# APM32F423 register map
File version: 1.0
CPU: CM4 r1p0, little endian, no MPU, no FPU, 4 interrupt priority bits
Registers are 32-bit, read-write, reset 0x0 unless marked. A register's access mark holds for its fields unless they carry their own. Offsets are from the block's base; [hi:lo] are bit positions; {n}, {i} and the like mark numbered series.

## OTG_FS1_GLOBAL — USB on the go full speed
Base 0x50000000
Same registers: OTG_FS2_GLOBAL 0x40040000
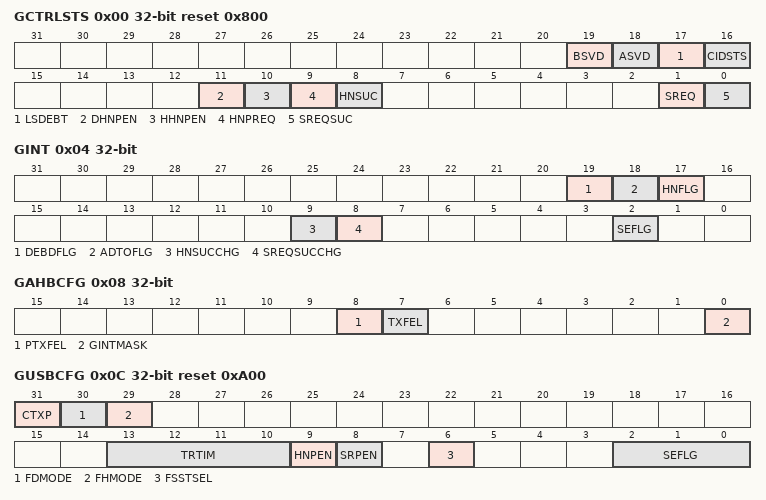
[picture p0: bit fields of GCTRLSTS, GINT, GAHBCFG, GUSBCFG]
0x00 GCTRLSTS access per field reset 0x800 — OTG_FS control and status register (OTG_FS_GOTGCTL)
  [19] BSVD ro — B-session valid
  [18] ASVD ro — A-session valid
  [17] LSDEBT ro — Long/short debounce time
  [16] CIDSTS ro — Connector ID status
  [11] DHNPEN rw — Device HNP enabled
  [10] HHNPEN rw — Host set HNP enable
  [9] HNPREQ rw — HNP request
  [8] HNSUC ro — Host negotiation success
  [1] SREQ rw — Session request
  [0] SREQSUC ro — Session request success
0x04 GINT — OTG_FS interrupt register (OTG_FS_GOTGINT)
  [19] DEBDFLG — Debounce done
  [18] ADTOFLG — A-device timeout change
  [17] HNFLG — Host negotiation detected
  [9] HNSUCCHG — Host negotiation success status change
  [8] SREQSUCCHG — Session request success status change
  [2] SEFLG — Session end detected
0x08 GAHBCFG — OTG_FS AHB configuration register (OTG_FS_GAHBCFG)
  [8] PTXFEL — Periodic TxFIFO empty level
  [7] TXFEL — TxFIFO empty level
  [0] GINTMASK — Global interrupt mask
0x0C GUSBCFG access per field reset 0xA00 — OTG_FS USB configuration register (OTG_FS_GUSBCFG)
  [31] CTXP rw — Corrupt Tx packet
  [30] FDMODE rw — Force device mode
  [29] FHMODE rw — Force host mode
  [13:10] TRTIM rw — USB turnaround time
  [9] HNPEN rw — HNP-capable
  [8] SRPEN rw — SRP-capable
  [6] FSSTSEL wo — Full Speed serial transceiver select
  [2:0] SEFLG rw — FS timeout calibration
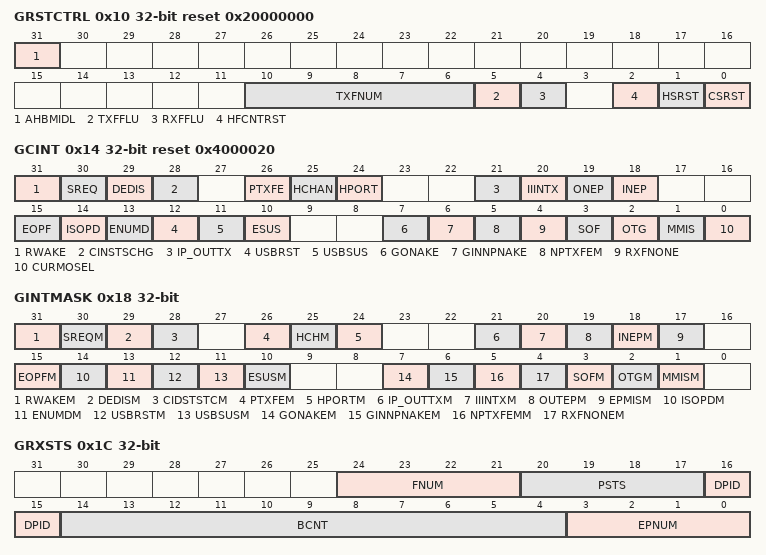
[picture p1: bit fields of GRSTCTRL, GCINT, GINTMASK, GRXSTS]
0x10 GRSTCTRL access per field reset 0x20000000 — OTG_FS reset register (OTG_FS_GRSTCTL)
  [31] AHBMIDL ro — AHB master idle
  [10:6] TXFNUM rw — TxFIFO number
  [5] TXFFLU rw — TxFIFO flush
  [4] RXFFLU rw — RxFIFO flush
  [2] HFCNTRST rw — Host frame counter reset
  [1] HSRST rw — HCLK soft reset
  [0] CSRST rw — Core soft reset
0x14 GCINT access per field reset 0x4000020 — OTG_FS core interrupt register (OTG_FS_GINTSTS)
  [31] RWAKE rw — Resume/remote wakeup detected interrupt
  [30] SREQ rw — Session request/new session detected interrupt
  [29] DEDIS rw — Disconnect detected interrupt
  [28] CINSTSCHG rw — Connector ID status change
  [26] PTXFE ro — Periodic TxFIFO empty
  [25] HCHAN ro — Host channels interrupt
  [24] HPORT ro — Host port interrupt
  [21] IP_OUTTX rw — Incomplete periodic transfer(Host mode)/Incomplete isochronous OUT transfer(Device mode)
  [20] IIINTX rw — Incomplete isochronous IN transfer
  [19] ONEP ro — OUT endpoint interrupt
  [18] INEP ro — IN endpoint interrupt
  [15] EOPF rw — End of periodic frame interrupt
  [14] ISOPD rw — Isochronous OUT packet dropped interrupt
  [13] ENUMD rw — Enumeration done
  [12] USBRST rw — USB reset
  [11] USBSUS rw — USB suspend
  [10] ESUS rw — Early suspend
  [7] GONAKE ro — Global OUT NAK effective
  [6] GINNPNAKE ro — Global IN non-periodic NAK effective
  [5] NPTXFEM ro — Non-periodic TxFIFO empty
  [4] RXFNONE ro — RxFIFO non-empty
  [3] SOF rw — Start of frame
  [2] OTG ro — OTG interrupt
  [1] MMIS rw — Mode mismatch interrupt
  [0] CURMOSEL ro — Current mode of operation
0x18 GINTMASK access per field — OTG_FS interrupt mask register (OTG_FS_GINTMSK)
  [31] RWAKEM rw — Resume/remote wakeup detected interrupt mask
  [30] SREQM rw — Session request/new session detected interrupt mask
  [29] DEDISM rw — Disconnect detected interrupt mask
  [28] CIDSTSTCM rw — Connector ID status change mask
  [26] PTXFEM rw — Periodic TxFIFO empty mask
  [25] HCHM rw — Host channels interrupt mask
  [24] HPORTM ro — Host port interrupt mask
  [21] IP_OUTTXM rw — Incomplete periodic transfer mask(Host mode)/Incomplete isochronous OUT transfer mask(Device mode)
  [20] IIINTXM rw — Incomplete isochronous IN transfer mask
  [19] OUTEPM rw — OUT endpoints interrupt mask
  [18] INEPM rw — IN endpoints interrupt mask
  [17] EPMISM rw — Endpoint mismatch interrupt mask
  [15] EOPFM rw — End of periodic frame interrupt mask
  [14] ISOPDM rw — Isochronous OUT packet dropped interrupt mask
  [13] ENUMDM rw — Enumeration done mask
  [12] USBRSTM rw — USB reset mask
  [11] USBSUSM rw — USB suspend mask
  [10] ESUSM rw — Early suspend mask
  [7] GONAKEM rw — Global OUT NAK effective mask
  [6] GINNPNAKEM rw — Global non-periodic IN NAK effective mask
  [5] NPTXFEMM rw — Non-periodic TxFIFO empty mask
  [4] RXFNONEM rw — Receive FIFO non-empty mask
  [3] SOFM rw — Start of frame mask
  [2] OTGM rw — OTG interrupt mask
  [1] MMISM rw — Mode mismatch interrupt mask
0x1C GRXSTS ro — OTG_FS Receive status debug read(Device mode)
  [24:21] FNUM — Frame number
  [20:17] PSTS — Packet status
  [16:15] DPID — Data PID
  [14:4] BCNT — Byte count
  [3:0] EPNUM — Endpoint number
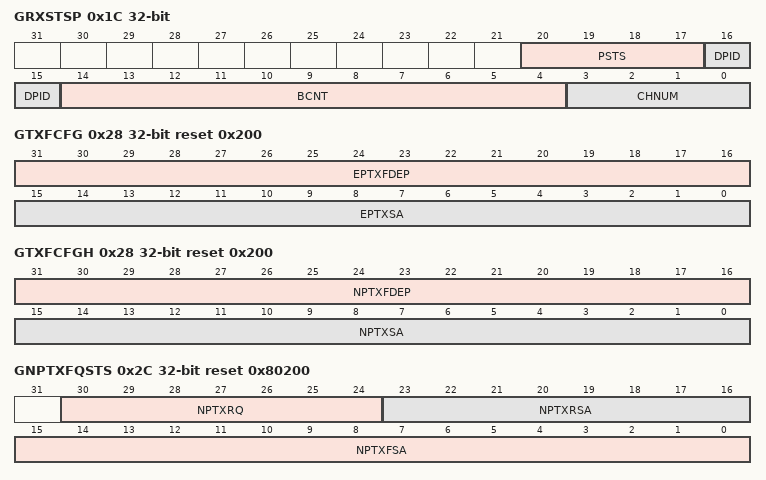
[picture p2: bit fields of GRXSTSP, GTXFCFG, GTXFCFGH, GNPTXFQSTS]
0x1C GRXSTSP ro (alternate view of GRXSTS) — OTG_FS Receive status debug read(Host mode)
  [20:17] PSTS — Packet status
  [16:15] DPID — Data PID
  [14:4] BCNT — Byte count
  [3:0] CHNUM — Endpoint number
0x24 GRXFIFO reset 0x200 — OTG_FS Receive FIFO size register (OTG_FS_GRXFSIZ)
  [15:0] RXFDEP — RxFIFO depth
0x28 GTXFCFG reset 0x200 — OTG_FS non-periodic transmit FIFO size register (Device mode)
  [31:16] EPTXFDEP — Endpoint 0 TxFIFO depth
  [15:0] EPTXSA — Endpoint 0 transmit RAM start address
0x28 GTXFCFGH reset 0x200 (alternate view of GTXFCFG) — OTG_FS non-periodic transmit FIFO size register (Host mode)
  [31:16] NPTXFDEP — Non-periodic TxFIFO depth
  [15:0] NPTXSA — Non-periodic transmit RAM start address
0x2C GNPTXFQSTS ro reset 0x80200 — OTG_FS non-periodic transmit FIFO/queue status register (OTG_FS_GNPTXFQSTS)
  [30:24] NPTXRQ — Top of the non-periodic transmit request queue
  [23:16] NPTXRSA — Non-periodic transmit request queue space available
  [15:0] NPTXFSA — Non-periodic TxFIFO space available
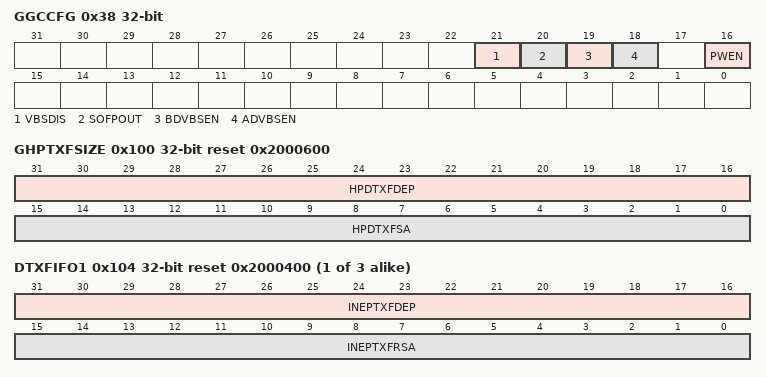
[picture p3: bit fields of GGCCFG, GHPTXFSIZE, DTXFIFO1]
0x38 GGCCFG — OTG_FS general core configuration register (OTG_FS_GCCFG)
  [21] VBSDIS — VBUS Sensing Disable
  [20] SOFPOUT — SOF output enable
  [19] BDVBSEN — Enable the VBUS sensing device
  [18] ADVBSEN — Enable the VBUS sensing device
  [16] PWEN — Power down
0x3C GCID reset 0x1000 — core ID register
  [31:0] PID — Product ID field
0x100 GHPTXFSIZE reset 0x2000600 — OTG_FS Host periodic transmit FIFO size register (OTG_FS_GHPTXFSIZE)
  [31:16] HPDTXFDEP — Host periodic TxFIFO depth
  [15:0] HPDTXFSA — Host periodic TxFIFO start address
{0x100+4i} DTXFIFO{i} reset 0x2000400 (i=1..3) — OTG_FS device IN endpoint transmit FIFO size register (OTG_FS_DTXFIFO{i})
  [31:16] INEPTXFDEP — IN endpoint TxFIFO depth
  [15:0] INEPTXFRSA — IN endpoint FIFO{i+1} transmit RAM start address
